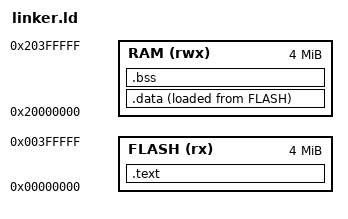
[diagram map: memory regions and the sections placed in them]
ENTRY(Reset_Handler)

MEMORY
{
  FLASH (rx)  : ORIGIN = 0x00000000, LENGTH = 4M
  RAM   (rwx) : ORIGIN = 0x20000000, LENGTH = 4M
}

_estack = ORIGIN(RAM) + LENGTH(RAM);

SECTIONS
{
  .text :
  {
    KEEP(*(.isr_vector))
    *(.text*)
    *(.rodata*)
  } > FLASH

  _sidata = LOADADDR(.data);

  .data :
  {
    _sdata = .;
    *(.data*)
    . = ALIGN(4);
    _edata = .;
  } > RAM AT> FLASH

  .bss :
  {
    _sbss = .;
    *(.bss*)
    *(COMMON)
    . = ALIGN(4);
    _ebss = .;
  } > RAM
}
